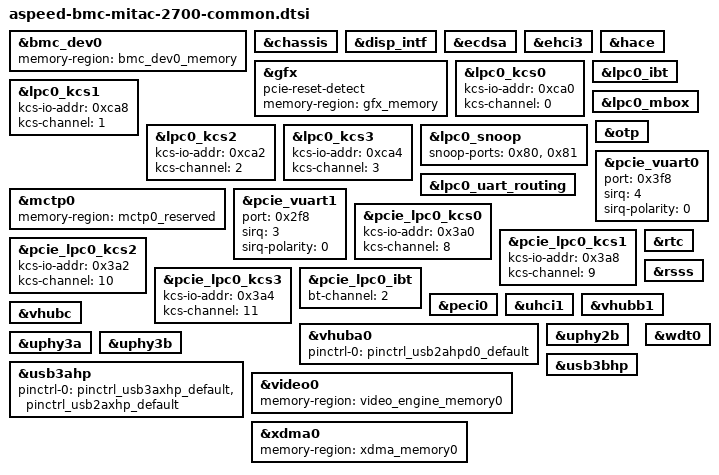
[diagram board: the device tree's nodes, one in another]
// SPDX-License-Identifier: GPL-2.0-or-later
// Copyright 2025 MiTAC-Computing Corp.

&bmc_dev0 {
    status = "okay";
    memory-region = <&bmc_dev0_memory>;
};

&chassis {
    status = "okay";
};

&disp_intf {
    status = "okay";
};

&ecdsa {
    status = "okay";
};

&ehci3 {
	status = "okay";
};

&gfx {
    pcie-reset-detect;
    status = "okay";
    memory-region = <&gfx_memory>;
};

&hace {
	status = "okay";
};

&lpc0_kcs0 {
    status = "okay";
    kcs-io-addr = <0xca0>;
    kcs-channel = <0>;
};

&lpc0_kcs1 {
	status = "okay";
	kcs-io-addr = <0xca8>;
	kcs-channel = <1>;
};

&lpc0_kcs2 {
	status = "okay";
	kcs-io-addr = <0xca2>;
	kcs-channel = <2>;
};

&lpc0_kcs3 {
	status = "okay";
	kcs-io-addr = <0xca4>;
	kcs-channel = <3>;
};

&lpc0_ibt {
	status = "okay";
};

&lpc0_mbox {
	status = "okay";
};

&lpc0_snoop {
	status = "okay";
	snoop-ports = <0x80>, <0x81>;
};

&lpc0_uart_routing {
	status = "okay";
};

&mctp0 {
	status = "okay";
	memory-region = <&mctp0_reserved>;
};

&otp {
	status = "okay";
};

&pcie_vuart0 {
	port = <0x3f8>;
	sirq = <4>;
	sirq-polarity = <0>;

	status = "okay";
};

&pcie_vuart1 {
	port = <0x2f8>;
	sirq = <3>;
	sirq-polarity = <0>;

	status = "okay";
};

&pcie_lpc0_kcs0 {
	status = "okay";
	kcs-io-addr = <0x3a0>;
	kcs-channel = <8>;
};

&pcie_lpc0_kcs1 {
	status = "okay";
	kcs-io-addr = <0x3a8>;
	kcs-channel = <9>;
};

&pcie_lpc0_kcs2 {
	status = "okay";
	kcs-io-addr = <0x3a2>;
	kcs-channel = <10>;
};

&pcie_lpc0_kcs3 {
	status = "okay";
	kcs-io-addr = <0x3a4>;
	kcs-channel = <11>;
};

&pcie_lpc0_ibt {
	status = "okay";
	bt-channel = <2>;
};

&peci0 {
    status = "okay";
};

&rtc {
	status = "okay";
};

&rsss {
	status = "okay";
};

&uhci1 {
	status = "okay";
};

&vhuba0 {
	status = "okay";
	pinctrl-0 = <&pinctrl_usb2ahpd0_default>;
};

&vhubb1 {
	status = "okay";
};

&vhubc {
	status = "okay";
};

&uphy2b {
	status = "okay";
};

&uphy3a {
	status = "okay";
};

&uphy3b {
	status = "okay";
};

&usb3ahp {
	status = "okay";
	pinctrl-0 = <&pinctrl_usb3axhp_default &pinctrl_usb2axhp_default>;
};

&usb3bhp {
	status = "okay";
};

&video0 {
	status = "okay";
	memory-region = <&video_engine_memory0>;
};

&wdt0 {
	status = "okay";
};

&xdma0 {
	status = "okay";
	memory-region = <&xdma_memory0>;
};

#include "aspeed-bmc-mitac-2700-common-node2.dtsi"
